# ISD91200B_v1 register map
File version: 1.0
Registers are 32-bit, read-write, reset 0x0 unless marked. A register's access mark holds for its fields unless they carry their own. Offsets are from the block's base; [hi:lo] are bit positions.

## PDMA0 — PDMA Register Map
Base 0x50008000
Same registers: PDMA1 0x50008100, PDMA2 0x50008200, PDMA3 0x50008300
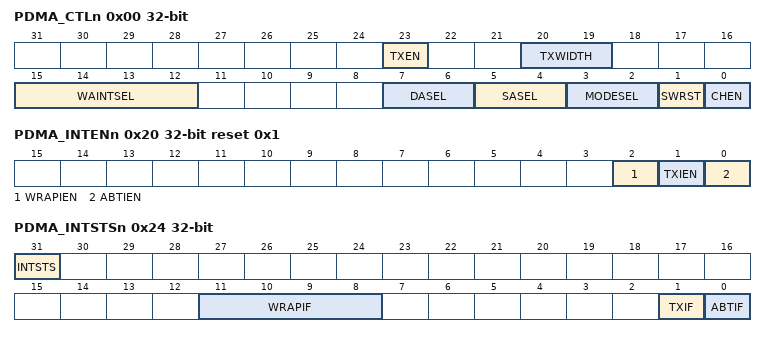
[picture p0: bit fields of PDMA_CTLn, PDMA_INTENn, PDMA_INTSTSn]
0x00 PDMA_CTLn — PDMA Control Register of Channel n
  [23] TXEN — Trigger Enable - Start a PDMA Operation. Note: When PDMA transfer completed, this bit will be cleared automatically. If a bus error occurs, all PDMA transfer will be stopped. Software must reset PDMA channel, and then trigger again.
    0=Write: no effect. Read: Idle/Finished; 1=Enable PDMA data read or write transfer
  [20:19] TXWIDTH — Peripheral Transfer Width Select. This parameter determines the data width to be transferred each PDMA transfer operation. Note: This field is meaningful only when MODESEL is IP to Memory mode (APB-to-Memory) or Memory to IP mode (Memory-to-APB).
    0=One word (32 bits) is transferred for every PDMA operation; 1=One byte (8 bits) is transferred for every PDMA operation; 2=One half-word (16 bits) is transferred for every PDMA operation
  [15:12] WAINTSEL — Wrap Interrupt Select x1x1: Both half and w interrupts generated.
  [7:6] DASEL — Destination Address Select. This parameter determines the behavior of the current destination address register with each PDMA transfer. It can either be fixed, incremented or wrapped. When PDMA_CTLn.CHEN is disabled, the PDMA will complete the active transfer but the remaining data in the SBUF will not be transferred to the destination address.
    0=Transfer Destination Address is incremented; 2=Transfer Destination Address is fixed (Used when data transferred from multiple addresses to a single destination such as peripheral FIFO input); 3=Transfer Destination Address is wrapped
  [5:4] SASEL — Source Address Select. This parameter determines the behavior of the current source address register with each PDMA transfer. It can either be fixed, incremented or wrapped. When PDMA_CTLn.CHEN is disabled, the PDMA will complete the active transfer but the remaining data in the SBUF will not be transferred to the destination address.
    0=Transfer Source address is incremented; 2=Transfer Source address is fixed; 3=Transfer Source address is wrapped
  [3:2] MODESEL — PDMA Mode Select. This parameter selects to transfer direction of the PDMA channel. Possible values are:
    0=Memory to Memory mode (SRAM-to-SRAM); 1=IP to Memory mode (APB-to-SRAM); 2=Memory to IP mode (SRAM-to-APB)
  [1] SWRST — Software Engine Reset
    0=Writing 0 to this bit has no effect; 1=Writing 1 to this bit will reset the internal state machine and pointers. The contents of the control register will not be cleared. This bit will auto clear after a few clock cycles
  [0] CHEN — PDMA Channel Enable. Setting this bit to 1 enables PDMA's operation. If this bit is cleared, PDMA will ignore all PDMA request and force Bus Master into IDLE state. Note: SWRST will clear this bit.
0x04 PDMA_SADDRn reset 0x40000000 — PDMA Transfer Source Address Register of Channel n
  [31:0] ADDR — PDMA Transfer Source Address Register. This register holds the initial Source Address of PDMA transfer. Note: The source address must be word aligned.
0x08 PDMA_DADDRn reset 0x40000000 — PDMA Transfer Destination Address Register of Channel n
  [31:0] ADDR — PDMA Transfer Destination Address Register. This register holds the initial Destination Address of PDMA transfer. Note: The destination address must be word aligned.
0x0C PDMA_TXCNTn — PDMA Transfer Byte Count Register of Channel n
  [15:0] CNT — PDMA Transfer Byte Count Register. This register controls the transfer byte count of PDMA. Maximum value is 0xFFFF.
0x10 PDMA_INTPNTn ro — PDMA Internal Buffer Pointer Register of Channel n
  [3:0] POINTER — PDMA Internal Buffer Pointer Register (Read Only). A PDMA transaction consists of two stages, a read from the source address and a write to the destination address. Internally this data is buffered in a 32bit register. If transaction width between the read and write transactions are different, this register tracks which byte/half-word of the internal buffer is being processed by the current transaction.
0x14 PDMA_CURSADDRn ro reset 0xFFFFFFFF — PDMA Current Source Address Register of Channel n
  [31:0] ADDR — PDMA Current Source Address Register (Read Only). This register returns the source address from which the PDMA transfer is occurring. This register is loaded from PDMA_SADDRn when PDMA is triggered or when a wraparound occurs.
0x18 PDMA_CURDADDRn ro reset 0xFFFFFFFF — PDMA Current Destination Address Register of Channel n
  [31:0] ADDR — PDMA Current Destination Address Register (Read Only). This register returns the destination address to which the PDMA transfer is occurring. This register is loaded from PDMA_DADDRn when PDMA is triggered or when a wraparound occurs.
0x1C PDMA_CURTXCNTn ro — PDMA Current Transfer Byte Count Register of Channel n
  [15:0] CNT — PDMA Current Byte Count Register (Read Only). This field indicates the current remaining byte count of PDMA transfer. This register is initialized with CNT register when PDMA is triggered or when a wraparound occurs
0x20 PDMA_INTENn reset 0x1 — PDMA Interrupt Enable Control Register of Channel n
  [2] WRAPIEN — Wraparound Interrupt Enable. If enabled, and channel source or destination address is in wraparound mode, the PDMA controller will generate a WRAP interrupt to the CPU according to the setting of. PDMA_DSCTn_CTL.WAINTSEL. This can be interrupts when the transaction has finished and has wrapped around and/or when the transaction is half way in progress. This allows the efficient implementation of circular buffers for DMA.
    0=Disable Wraparound PDMA interrupt generation; 1=Enable Wraparound interrupt generation
  [1] TXIEN — PDMA Transfer Done Interrupt Enable. If enabled, the PDMA controller will generate and interrupt to the CPU when the requested PDMA transfer is complete.
    0=Disable PDMA transfer done interrupt generation; 1=Enable PDMA transfer done interrupt generation
  [0] ABTIEN — PDMA Read/Write Target Abort Interrupt Enable. If enabled, the PDMA controller will generate and interrupt to the CPU whenever a PDMA transaction is aborted due to an error. If a transfer is aborted, PDMA channel must be reset to resume DMA operation.
    0=Disable PDMA transfer target abort interrupt generation; 1=Enable PDMA transfer target abort interrupt generation
0x24 PDMA_INTSTSn — PDMA Interrupt Status Register of Channel n
  [31] INTSTS ro — Interrupt Pin Status (Read Only). This bit is the Interrupt pin status of PDMA channel.
  [11:8] WRAPIF — Wrap Around Transfer Byte Count Interrupt Flag. These flags are set whenever the conditions for a wraparound interrupt (complete or half complete) are met. They are cleared by writing one to the bits.
    1=Current transfer finished flag (PDMA_CURTXCNT == 0); 4=Current transfer half complete flag (PDMA_CURTXCNT == PDMA_TXCNT /2)
  [1] TXIF — Block Transfer Done Interrupt Flag. This bit indicates that PDMA block transfer complete interrupt has been generated. It is cleared by writing 1 to the bit.
    0=Transfer ongoing or Idle; 1=Transfer Complete
  [0] ABTIF — PDMA Read/Write Target Abort Interrupt Flag. This flag indicates a Target Abort interrupt condition has occurred. This condition can happen if attempt is made to read/write from invalid or non-existent memory space. It occurs when PDMA controller receives a bus error from AHB master. Upon occurrence PDMA will stop transfer and go to idle state. To resume, software must reset PDMA channel and initiate transfer again. NOTE: This bit is cleared by writing 1 to itself.
    0=No bus ERROR response received; 1=Bus ERROR response received
0x34 PDMA_SPANn ro — PDMA Span Increment Register of Channel n
  [7:0] SPAN — Span Increment Register. This is a signed number in range [-128,127] for use in spanned address mode. If destination or source addressing mode is set as spanned, then this number is added to the address register each transfer. The size of the transfer is determined by the APB_TW setting. Note that span increment must be a multiple of the transfer width otherwise a memory addressing HardFault will occur. Also SPAN may be a negative number.
0x38 PDMA_CURSPANn — PDMA Current Span Increment Register of Channel n
  [7:0] SPAN — Current Span Increment Register. This is a signed read only register for use in spanned address mode. It provides the current address offset from SADDR or DADDR if either is set to span mode.
